# CC1312PSIP register map
File version: 1.0
CPU: CM4 1.0, other endian, MPU, FPU, 3 interrupt priority bits
Registers are 32-bit, read-write, reset 0x0 unless marked. A register's access mark holds for its fields unless they carry their own. Offsets are from the block's base; [hi:lo] are bit positions; {n}, {i} and the like mark numbered series; 'fields as' and 'values as' point back to an identical list.

## AON_EVENT — This module configures the event fabric located in the AON domain. Note: This module is only supporting 32 bit ReadWrite access from MCU
Base 0x40093000
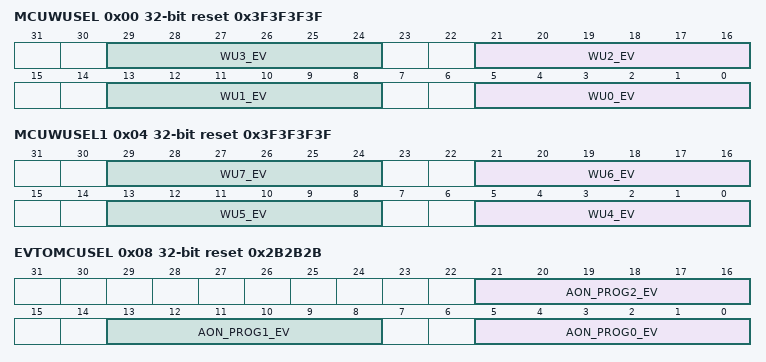
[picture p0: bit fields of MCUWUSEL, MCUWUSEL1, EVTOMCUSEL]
0x00 MCUWUSEL reset 0x3F3F3F3F — Wake-up Selector For MCU This register contains pointers to 4 of 8 events (events 0 to 3) which are routed to AON_PMCTRL as wakeup sources for MCU. AON_PMCTRL will start a wakeup sequence for the MCU domain when either of the 8 selected events are asserted. A wakeup sequence will guarantee that the MCU power switches are turned on, LDO resources are available and SCLK_HF is available and selected as clock source for MCU. Note: It is required to setup a wakeup event in AON_EVENT before MCU is requesting powerdown ( PRCM requests uLDO, see conditions in PRCM:VDCTL.ULDO ).
  [all] fields
    63=NONE (No event, always low); 56=AUX_COMPB_ASYNC_N (Comparator B not triggered. Asynchronous signal directly from AUX Comparator B (inverted) as opposed to AUX_COMPB which is synchronized in AUX); 55=AUX_COMPB_ASYNC (Comparator B triggered. Asynchronous signal directly from the AUX Comparator B as opposed to AUX_COMPB which is synchronized in AUX); 54=BATMON_VOLT (BATMON voltage update event); 53=BATMON_TEMP (BATMON temperature update event); 52=AUX_TIMER1_EV (AUX Timer 1 Event); 51=AUX_TIMER0_EV (AUX Timer 0 Event); 50=AUX_TDC_DONE (TDC completed or timed out); 49=AUX_ADC_DONE (ADC conversion completed); 48=AUX_COMPB (Comparator B triggered); 47=AUX_COMPA (Comparator A triggered); 46=AUX_SWEV2 (AUX Software triggered event #2. Triggered by AUX_EVCTL:SWEVSET.SWEV2); 45=AUX_SWEV1 (AUX Software triggered event #1. Triggered by AUX_EVCTL:SWEVSET.SWEV1); 44=AUX_SWEV0 (AUX Software triggered event #0. Triggered by AUX_EVCTL:SWEVSET.SWEV0); 43=JTAG (JTAG generated event); 42=RTC_UPD (RTC Update Tick (16 kHz signal, i.e. event line toggles value every 32 kHz clock period)); 41=RTC_COMB_DLY (RTC combined delayed event); 40=RTC_CH2_DLY (RTC channel 2 - delayed event); 39=RTC_CH1_DLY (RTC channel 1 - delayed event); 38=RTC_CH0_DLY (RTC channel 0 - delayed event); 37=RTC_CH2 (RTC channel 2 event); 36=RTC_CH1 (RTC channel 1 event); 35=RTC_CH0 (RTC channel 0 event); 32=PAD (Edge detect on any PAD); 9=BATMON_COMBINED (Combined event from BATMON); 8=BATMON_TEMP_LL (BATMON event: Temperature level below lower limit); 7=BATMON_TEMP_UL (BATMON event: Temperature level above upper limit); 6=BATMON_BATT_LL (BATMON event: Battery level below lower limit); 5=BATMON_BATT_UL (BATMON event: Battery level above upper limit); {v}=AUX_TIMER2_EV{v-1} (Event {v-1} from AUX TImer2) (v=1..4); 0=IOEV_MCU_WU (Edge detect IO event from the DIO(s) which have enabled contribution to IOEV_MCU_WU in [MCU_IOC:IOCFGx.IOEV_MCU_WU_EN])
  [8n+5:8n] WU{n}_EV (n=0..3) — [{8n+5}:{8n}] MCU Wakeup Source #{n} AON Event Source selecting 1 of 8 events routed to AON_PMCTRL for waking up the MCU domain from Power Off or Power Down. Note:
0x04 MCUWUSEL1 reset 0x3F3F3F3F — Wake-up Selector For MCU This register contains pointers to 4 of 8 events (events 4 to 7) which are routed to AON_PMCTRL as wakeup sources for MCU. AON_PMCTRL will start a wakeup sequence for the MCU domain when either of the 8 selected events are asserted. A wakeup sequence will guarantee that the MCU power switches are turned on, LDO resources are available and SCLK_HF is available and selected as clock source for MCU. Note: It is required to setup a wakeup event in AON_EVENT before MCU is requesting powerdown ( PRCM requests uLDO, see conditions in PRCM:VDCTL.ULDO ).
  [all] fields
    values as the fields of MCUWUSEL
  [8n-27:8n-32] WU{n}_EV (n=4..7) — [{8n-27}:{8n-32}] MCU Wakeup Source #{n} AON Event Source selecting 1 of 8 events routed to AON_PMCTRL for waking up the MCU domain from Power Off or Power Down. Note:
0x08 EVTOMCUSEL reset 0x2B2B2B — Event Selector For MCU Event Fabric This register contains pointers for 3 AON events that are routed to the MCU Event Fabric EVENT
  [21:16] AON_PROG2_EV — [21:16] Event selector for AON_PROG2 event. AON Event Source id# selecting event routed to EVENT as AON_PROG2 event.
    63=NONE (No event, always low); 56=AUX_COMPB_ASYNC_N (Comparator B not triggered. Asynchronous signal directly from AUX Comparator B (inverted) as opposed to AUX_COMPB which is synchronized in AUX); 55=AUX_COMPB_ASYNC (Comparator B triggered. Asynchronous signal directly from the AUX Comparator B as opposed to AUX_COMPB which is synchronized in AUX); 54=BATMON_VOLT (BATMON voltage update event); 53=BATMON_TEMP (BATMON temperature update event); 52=AUX_TIMER1_EV (AUX Timer 1 Event); 51=AUX_TIMER0_EV (AUX Timer 0 Event); 50=AUX_TDC_DONE (TDC completed or timed out); 49=AUX_ADC_DONE (ADC conversion completed); 48=AUX_COMPB (Comparator B triggered); 47=AUX_COMPA (Comparator A triggered); 46=AUX_SWEV2 (AUX Software triggered event #2. Triggered by AUX_EVCTL:SWEVSET.SWEV2); 45=AUX_SWEV1 (AUX Software triggered event #1. Triggered by AUX_EVCTL:SWEVSET.SWEV1); 44=AUX_SWEV0 (AUX Software triggered event #0. Triggered by AUX_EVCTL:SWEVSET.SWEV0); 43=JTAG (JTAG generated event); 42=RTC_UPD (RTC Update Tick (16 kHz signal, i.e. event line toggles value every 32 kHz clock period)); 41=RTC_COMB_DLY (RTC combined delayed event); 40=RTC_CH2_DLY (RTC channel 2 - delayed event); 39=RTC_CH1_DLY (RTC channel 1 - delayed event); 38=RTC_CH0_DLY (RTC channel 0 - delayed event); 37=RTC_CH2 (RTC channel 2 event); 36=RTC_CH1 (RTC channel 1 event); 35=RTC_CH0 (RTC channel 0 event); 32=PAD (Edge detect on any PAD); 9=BATMON_COMBINED (Combined event from BATMON); 8=BATMON_TEMP_LL (BATMON event: Temperature level below lower limit); 7=BATMON_TEMP_UL (BATMON event: Temperature level above upper limit); 6=BATMON_BATT_LL (BATMON event: Battery level below lower limit); 5=BATMON_BATT_UL (BATMON event: Battery level above upper limit); {v}=AUX_TIMER2_EV{v-1} (Event {v-1} from AUX TImer2) (v=1..4); 0=IOEV_AON_PROG2 (Edge detect IO event from the DIO(s) which have enabled contribution to IOEV_AON_PROG2 in [MCU_IOC:IOCFGx.IOEV_AON_PROG2_EN])
  [13:8] AON_PROG1_EV — [13:8] Event selector for AON_PROG1 event. AON Event Source id# selecting event routed to EVENT as AON_PROG1 event.
    63=NONE (0); 56=AUX_COMPB_ASYNC_N (0); 55=AUX_COMPB_ASYNC (0); 54=BATMON_VOLT (0); 53=BATMON_TEMP (0); 52=AUX_TIMER1_EV (0); 51=AUX_TIMER0_EV (0); 50=AUX_TDC_DONE (0); 49=AUX_ADC_DONE (0); 48=AUX_COMPB (0); 47=AUX_COMPA (0); 46=AUX_SWEV2 (0); 45=AUX_SWEV1 (0); 44=AUX_SWEV0 (0); 43=JTAG (0); 42=RTC_UPD (0); 41=RTC_COMB_DLY (0); 40=RTC_CH2_DLY (0); 39=RTC_CH1_DLY (0); 38=RTC_CH0_DLY (RTC channel 0 - delayed event); 37=RTC_CH2 (RTC channel 2 event); 36=RTC_CH1 (RTC channel 1 event); 35=RTC_CH0 (RTC channel 0 event); 32=PAD (Edge detect on any PAD); 9=BATMON_COMBINED (Combined event from BATMON); 8=BATMON_TEMP_LL (BATMON event: Temperature level below lower limit); 7=BATMON_TEMP_UL (BATMON event: Temperature level above upper limit); 6=BATMON_BATT_LL (BATMON event: Battery level below lower limit); 5=BATMON_BATT_UL (BATMON event: Battery level above upper limit); {v}=AUX_TIMER2_EV{v-1} (Event {v-1} from AUX TImer2) (v=1..4); 0=IOEV_AON_PROG1 (Edge detect IO event from the DIO(s) which have enabled contribution to IOEV_AON_PROG1 in [MCU_IOC:IOCFGx.IOEV_AON_PROG1_EN])
  [5:0] AON_PROG0_EV — [5:0] Event selector for AON_PROG0 event. AON Event Source id# selecting event routed to EVENT as AON_PROG0 event.
    63=NONE (0); 56=AUX_COMPB_ASYNC_N (0); 55=AUX_COMPB_ASYNC (0); 54=BATMON_VOLT (0); 53=BATMON_TEMP (0); 52=AUX_TIMER1_EV (0); 51=AUX_TIMER0_EV (0); 50=AUX_TDC_DONE (0); 49=AUX_ADC_DONE (0); 48=AUX_COMPB (0); 47=AUX_COMPA (0); 46=AUX_SWEV2 (0); 45=AUX_SWEV1 (0); 44=AUX_SWEV0 (0); 43=JTAG (0); 42=RTC_UPD (0); 41=RTC_COMB_DLY (0); 40=RTC_CH2_DLY (0); 39=RTC_CH1_DLY (0); 38=RTC_CH0_DLY (0); 37=RTC_CH2 (0); 36=RTC_CH1 (0); 35=RTC_CH0 (0); 32=PAD (0); 9=BATMON_COMBINED (0); 8=BATMON_TEMP_LL (0); 7=BATMON_TEMP_UL (0); 6=BATMON_BATT_LL (0); 5=BATMON_BATT_UL (0); {v}=AUX_TIMER2_EV{v-1} (0) (v=1..4); 0=IOEV_AON_PROG0 (Edge detect IO event from the DIO(s) which have enabled contribution to IOEV_AON_PROG0 in [MCU_IOC:IOCFGx.IOEV_AON_PROG0_EN])
0x0C RTCSEL reset 0x3F — RTC Capture Event Selector For AON_RTC This register contains a pointer to select an AON event for RTC capture. Please refer to AON_RTC:CH1CAPT
  [5:0] RTC_CH1_CAPT_EV — [5:0] AON Event Source id# for RTCSEL event which is fed to AON_RTC. Please refer to AON_RTC:CH1CAPT
    63=NONE (0); 56=AUX_COMPB_ASYNC_N (0); 55=AUX_COMPB_ASYNC (0); 54=BATMON_VOLT (0); 53=BATMON_TEMP (0); 52=AUX_TIMER1_EV (0); 51=AUX_TIMER0_EV (0); 50=AUX_TDC_DONE (0); 49=AUX_ADC_DONE (0); 48=AUX_COMPB (0); 47=AUX_COMPA (0); 46=AUX_SWEV2 (0); 45=AUX_SWEV1 (0); 44=AUX_SWEV0 (0); 43=JTAG (0); 42=RTC_UPD (0); 41=RTC_COMB_DLY (0); 40=RTC_CH2_DLY (0); 39=RTC_CH1_DLY (0); 38=RTC_CH0_DLY (0); 37=RTC_CH2 (0); 36=RTC_CH1 (0); 35=RTC_CH0 (0); 32=PAD (0); 9=BATMON_COMBINED (0); 8=BATMON_TEMP_LL (0); 7=BATMON_TEMP_UL (0); 6=BATMON_BATT_LL (0); 5=BATMON_BATT_UL (0); {v}=AUX_TIMER2_EV{v-1} (0) (v=1..4); 0=IOEV_RTC (Edge detect IO event from the DIO(s) which have enabled contribution to IOEV_RTC in [MCU_IOC:IOCFGx.IOEV_RTC_EN])
